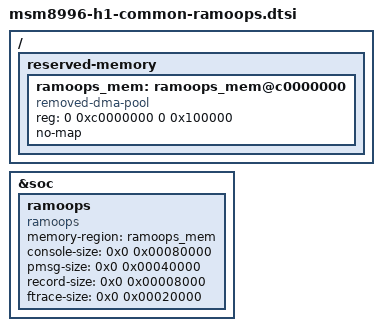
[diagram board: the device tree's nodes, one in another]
/ {
	reserved-memory {
		ramoops_mem: ramoops_mem@c0000000 {
			compatible = "removed-dma-pool";
			reg = <0 0xc0000000 0 0x100000>;
			no-map;
		};
	};
};

&soc {
	ramoops {
		compatible = "ramoops";
		status = "ok";
		memory-region = <&ramoops_mem>;
		console-size = <0x0 0x00080000>;
		pmsg-size    = <0x0 0x00040000>;
		record-size  = <0x0 0x00008000>;
		ftrace-size  = <0x0 0x00020000>;
	};
};
